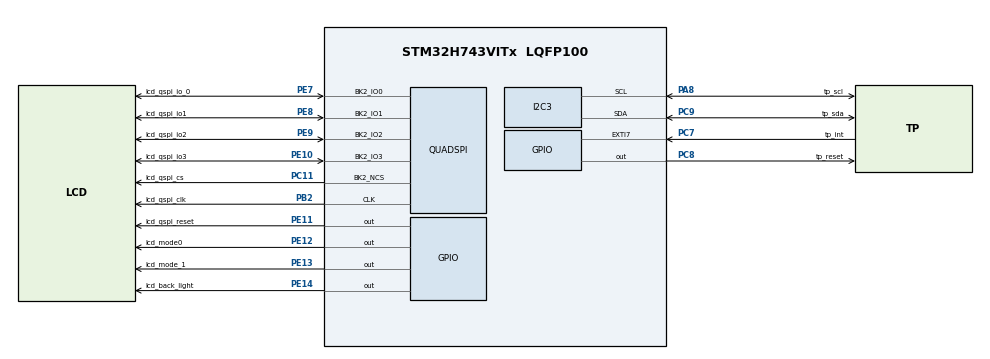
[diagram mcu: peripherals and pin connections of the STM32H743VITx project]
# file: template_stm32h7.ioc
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CORTEX_M7.default_mode_Activation=1
Dma.I2C3_RX.0.Direction=DMA_PERIPH_TO_MEMORY
Dma.I2C3_RX.0.EventEnable=DISABLE
Dma.I2C3_RX.0.FIFOMode=DMA_FIFOMODE_DISABLE
Dma.I2C3_RX.0.Instance=DMA1_Stream1
Dma.I2C3_RX.0.MemDataAlignment=DMA_MDATAALIGN_BYTE
Dma.I2C3_RX.0.MemInc=DMA_MINC_ENABLE
Dma.I2C3_RX.0.Mode=DMA_NORMAL
Dma.I2C3_RX.0.PeriphDataAlignment=DMA_PDATAALIGN_BYTE
Dma.I2C3_RX.0.PeriphInc=DMA_PINC_DISABLE
Dma.I2C3_RX.0.Polarity=HAL_DMAMUX_REQ_GEN_RISING
Dma.I2C3_RX.0.Priority=DMA_PRIORITY_MEDIUM
Dma.I2C3_RX.0.RequestNumber=1
Dma.I2C3_RX.0.SignalID=NONE
Dma.I2C3_RX.0.SyncEnable=DISABLE
Dma.I2C3_RX.0.SyncPolarity=HAL_DMAMUX_SYNC_NO_EVENT
Dma.I2C3_RX.0.SyncRequestNumber=1
Dma.I2C3_RX.0.SyncSignalID=NONE
Dma.Request0=I2C3_RX
FREERTOS.Queues01=queue_default,1,uint32_t,0,Dynamic,NULL,NULL
FREERTOS.Tasks01=task_default,24,128,task_default_start,Default,NULL,Dynamic,NULL,NULL
I2C3.CustomTiming=Disabled
I2C3.Speed=100
I2C3.Timing=0x307075B1
Mcu.Family=STM32H7
Mcu.Name=STM32H743VITx
Mcu.Package=LQFP100
NVIC.DMA1_Stream1_IRQn=true\:6\:0\:true\:false\:true\:true\:false\:true\:true
NVIC.EXTI9_5_IRQn=true\:7\:0\:true\:false\:true\:true\:true\:true\:true
NVIC.PriorityGroup=NVIC_PRIORITYGROUP_4
NVIC.TIM6_DAC_IRQn=true\:15\:0\:false\:false\:true\:false\:false\:true\:true
NVIC.TimeBase=TIM6_DAC_IRQn
NVIC.TimeBaseIP=TIM6
PA13\ (JTMS/SWDIO).Mode=Serial_Wire
PA13\ (JTMS/SWDIO).Signal=DEBUG_JTMS-SWDIO
PA14\ (JTCK/SWCLK).Mode=Serial_Wire
PA14\ (JTCK/SWCLK).Signal=DEBUG_JTCK-SWCLK
PA8.GPIO_Label=tp_scl
PA8.GPIO_Speed=GPIO_SPEED_FREQ_VERY_HIGH
PA8.Mode=I2C
PA8.Signal=I2C3_SCL
PB2.GPIO_Label=lcd_qspi_clk
PB2.GPIO_Speed=GPIO_SPEED_FREQ_VERY_HIGH
PB2.Mode=Single Bank 2
PB2.Signal=QUADSPI_CLK
PC11.GPIO_Label=lcd_qspi_cs
PC11.GPIO_PuPd=GPIO_PULLDOWN
PC11.GPIO_Speed=GPIO_SPEED_FREQ_VERY_HIGH
PC11.Mode=Single Bank 2
PC11.Signal=QUADSPI_BK2_NCS
PC14-OSC32_IN\ (OSC32_IN).Mode=LSE-External-Oscillator
PC14-OSC32_IN\ (OSC32_IN).Signal=RCC_OSC32_IN
PC15-OSC32_OUT\ (OSC32_OUT).Mode=LSE-External-Oscillator
PC15-OSC32_OUT\ (OSC32_OUT).Signal=RCC_OSC32_OUT
PC7.GPIO_Label=tp_int
PC7.GPIO_ModeDefaultEXTI=GPIO_MODE_IT_FALLING
PC7.GPIO_PuPd=GPIO_PULLUP
PC7.Signal=GPXTI7
PC8.GPIO_Label=tp_reset
PC8.GPIO_Speed=GPIO_SPEED_FREQ_VERY_HIGH
PC8.PinState=GPIO_PIN_SET
PC8.Signal=GPIO_Output
PC9.GPIO_Label=tp_sda
PC9.GPIO_Speed=GPIO_SPEED_FREQ_VERY_HIGH
PC9.Mode=I2C
PC9.Signal=I2C3_SDA
PE10.GPIO_Label=lcd_qspi_io3
PE10.GPIO_Speed=GPIO_SPEED_FREQ_VERY_HIGH
PE10.Mode=Single Bank 2
PE10.Signal=QUADSPI_BK2_IO3
PE11.GPIO_Label=lcd_qspi_reset
PE11.GPIO_Speed=GPIO_SPEED_FREQ_VERY_HIGH
PE11.PinState=GPIO_PIN_SET
PE11.Signal=GPIO_Output
PE12.GPIO_Label=lcd_mode0
PE12.GPIO_Speed=GPIO_SPEED_FREQ_VERY_HIGH
PE12.Signal=GPIO_Output
PE13.GPIO_Label=lcd_mode_1
PE13.GPIO_Speed=GPIO_SPEED_FREQ_VERY_HIGH
PE13.PinState=GPIO_PIN_SET
PE13.Signal=GPIO_Output
PE14.GPIO_Label=lcd_back_light
PE14.GPIO_Speed=GPIO_SPEED_FREQ_VERY_HIGH
PE14.PinState=GPIO_PIN_SET
PE14.Signal=GPIO_Output
PE7.GPIO_Label=lcd_qspi_io_0
PE7.GPIO_Speed=GPIO_SPEED_FREQ_VERY_HIGH
PE7.Mode=Single Bank 2
PE7.Signal=QUADSPI_BK2_IO0
PE8.GPIO_Label=lcd_qspi_io1
PE8.GPIO_Speed=GPIO_SPEED_FREQ_VERY_HIGH
PE8.Mode=Single Bank 2
PE8.Signal=QUADSPI_BK2_IO1
PE9.GPIO_Label=lcd_qspi_io2
PE9.GPIO_Speed=GPIO_SPEED_FREQ_VERY_HIGH
PE9.Mode=Single Bank 2
PE9.Signal=QUADSPI_BK2_IO2
PH0-OSC_IN\ (PH0).Mode=HSE-External-Oscillator
PH0-OSC_IN\ (PH0).Signal=RCC_OSC_IN
PH1-OSC_OUT\ (PH1).Mode=HSE-External-Oscillator
PH1-OSC_OUT\ (PH1).Signal=RCC_OSC_OUT
ProjectManager.HeapSize=0x200
ProjectManager.StackSize=0x400
ProjectManager.TargetToolchain=Makefile
RCC.ADCFreq_Value=100000000
RCC.APB1Freq_Value=120000000
RCC.APB2Freq_Value=120000000
RCC.APB3Freq_Value=120000000
RCC.APB4Freq_Value=120000000
RCC.CortexFreq_Value=480000000
RCC.D1PPRE=RCC_APB3_DIV2
RCC.D2PPRE1=RCC_APB1_DIV2
RCC.D2PPRE2=RCC_APB2_DIV2
RCC.D3PPRE=RCC_APB4_DIV2
RCC.DIVM1=5
RCC.DIVM2=16
RCC.DIVN1=192
RCC.DIVN2=128
RCC.DIVR2=4
RCC.HCLKFreq_Value=240000000
RCC.HPRE=RCC_HCLK_DIV2
RCC.PLLSourceVirtual=RCC_PLLSOURCE_HSE
RCC.QSPICLockSelection=RCC_QSPICLKSOURCE_PLL2
RCC.SYSCLKFreq_VALUE=480000000
RCC.SYSCLKSource=RCC_SYSCLKSOURCE_PLLCLK
RCC.USBFreq_Value=480000000
VP_FREERTOS_VS_CMSIS_V2.Mode=CMSIS_V2
VP_MEMORYMAP_VS_MEMORYMAP.Mode=CurAppReg
VP_RTC_VS_RTC_Activate.Mode=RTC_Enabled
VP_SYS_VS_tim6.Mode=TIM6
board=custom

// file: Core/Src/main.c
/* USER CODE BEGIN Header */
/**
  ******************************************************************************
  * @file           : main.c
  * @brief          : Main program body
  ******************************************************************************
  * @attention
  *
  * Copyright (c) 2025 STMicroelectronics.
  * All rights reserved.
  *
  * This software is licensed under terms that can be found in the LICENSE file
  * in the root directory of this software component.
  * If no LICENSE file comes with this software, it is provided AS-IS.
  *
  ******************************************************************************
  */
/* USER CODE END Header */
#include "main.h"
#include "cmsis_os.h"
#include "dma.h"
#include "i2c.h"
#include "memorymap.h"
#include "quadspi.h"
#include "rtc.h"
#include "gpio.h"

/* USER CODE BEGIN Includes */
#include "driver_st77916.h"
/* USER CODE END Includes */

void SystemClock_Config(void);
static void MPU_Config(void);
void MX_FREERTOS_Init(void);

int main(void)
{

  /* MPU Configuration--------------------------------------------------------*/
  MPU_Config();

  /* MCU Configuration--------------------------------------------------------*/

  /* Reset of all peripherals, Initializes the Flash interface and the Systick. */
  HAL_Init();

  /* Configure the system clock */
  SystemClock_Config();

  /* Initialize all configured peripherals */
  MX_GPIO_Init();
  MX_DMA_Init();
  MX_RTC_Init();
  MX_I2C3_Init();
  MX_QUADSPI_Init();
  /* USER CODE BEGIN 2 */
  driver_st77916_init();
  /* USER CODE END 2 */

  /* Init scheduler */
  osKernelInitialize();

  /* Call init function for freertos objects (in cmsis_os2.c) */
  MX_FREERTOS_Init();

  /* Start scheduler */
  osKernelStart();

  /* We should never get here as control is now taken by the scheduler */

  /* Infinite loop */
  while (1)
  {

  }
}

void SystemClock_Config(void)
{
  RCC_OscInitTypeDef RCC_OscInitStruct = {0};
  RCC_ClkInitTypeDef RCC_ClkInitStruct = {0};

  /** Supply configuration update enable
  */
  HAL_PWREx_ConfigSupply(PWR_LDO_SUPPLY);

  /** Configure the main internal regulator output voltage
  */
  __HAL_PWR_VOLTAGESCALING_CONFIG(PWR_REGULATOR_VOLTAGE_SCALE0);

  while(!__HAL_PWR_GET_FLAG(PWR_FLAG_VOSRDY)) {}

  /** Initializes the RCC Oscillators according to the specified parameters
  * in the RCC_OscInitTypeDef structure.
  */
  RCC_OscInitStruct.OscillatorType = RCC_OSCILLATORTYPE_LSI|RCC_OSCILLATORTYPE_HSE;
  RCC_OscInitStruct.HSEState = RCC_HSE_ON;
  RCC_OscInitStruct.LSIState = RCC_LSI_ON;
  RCC_OscInitStruct.PLL.PLLState = RCC_PLL_ON;
  RCC_OscInitStruct.PLL.PLLSource = RCC_PLLSOURCE_HSE;
  RCC_OscInitStruct.PLL.PLLM = 5;
  RCC_OscInitStruct.PLL.PLLN = 192;
  RCC_OscInitStruct.PLL.PLLP = 2;
  RCC_OscInitStruct.PLL.PLLQ = 2;
  RCC_OscInitStruct.PLL.PLLR = 2;
  RCC_OscInitStruct.PLL.PLLRGE = RCC_PLL1VCIRANGE_2;
  RCC_OscInitStruct.PLL.PLLVCOSEL = RCC_PLL1VCOWIDE;
  RCC_OscInitStruct.PLL.PLLFRACN = 0;
  if (HAL_RCC_OscConfig(&RCC_OscInitStruct) != HAL_OK)
  {
    Error_Handler();
  }

  /** Initializes the CPU, AHB and APB buses clocks
  */
  RCC_ClkInitStruct.ClockType = RCC_CLOCKTYPE_HCLK|RCC_CLOCKTYPE_SYSCLK
                              |RCC_CLOCKTYPE_PCLK1|RCC_CLOCKTYPE_PCLK2
                              |RCC_CLOCKTYPE_D3PCLK1|RCC_CLOCKTYPE_D1PCLK1;
  RCC_ClkInitStruct.SYSCLKSource = RCC_SYSCLKSOURCE_PLLCLK;
  RCC_ClkInitStruct.SYSCLKDivider = RCC_SYSCLK_DIV1;
  RCC_ClkInitStruct.AHBCLKDivider = RCC_HCLK_DIV2;
  RCC_ClkInitStruct.APB3CLKDivider = RCC_APB3_DIV2;
  RCC_ClkInitStruct.APB1CLKDivider = RCC_APB1_DIV2;
  RCC_ClkInitStruct.APB2CLKDivider = RCC_APB2_DIV2;
  RCC_ClkInitStruct.APB4CLKDivider = RCC_APB4_DIV2;

  if (HAL_RCC_ClockConfig(&RCC_ClkInitStruct, FLASH_LATENCY_4) != HAL_OK)
  {
    Error_Handler();
  }
}

 /* MPU Configuration */

void MPU_Config(void)
{
  MPU_Region_InitTypeDef MPU_InitStruct = {0};

  /* Disables the MPU */
  HAL_MPU_Disable();

  /** Initializes and configures the Region and the memory to be protected
  */
  MPU_InitStruct.Enable = MPU_REGION_ENABLE;
  MPU_InitStruct.Number = MPU_REGION_NUMBER0;
  MPU_InitStruct.BaseAddress = 0x0;
  MPU_InitStruct.Size = MPU_REGION_SIZE_4GB;
  MPU_InitStruct.SubRegionDisable = 0x87;
  MPU_InitStruct.TypeExtField = MPU_TEX_LEVEL0;
  MPU_InitStruct.AccessPermission = MPU_REGION_NO_ACCESS;
  MPU_InitStruct.DisableExec = MPU_INSTRUCTION_ACCESS_DISABLE;
  MPU_InitStruct.IsShareable = MPU_ACCESS_SHAREABLE;
  MPU_InitStruct.IsCacheable = MPU_ACCESS_NOT_CACHEABLE;
  MPU_InitStruct.IsBufferable = MPU_ACCESS_NOT_BUFFERABLE;

  HAL_MPU_ConfigRegion(&MPU_InitStruct);
  /* Enables the MPU */
  HAL_MPU_Enable(MPU_PRIVILEGED_DEFAULT);

}

void HAL_TIM_PeriodElapsedCallback(TIM_HandleTypeDef *htim)
{
  if (htim->Instance == TIM6)
  {
    HAL_IncTick();
  }
}

void Error_Handler(void)
{
  __disable_irq();
  while (1)
  {
  }
}

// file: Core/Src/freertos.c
/* USER CODE BEGIN Header */
/**
  ******************************************************************************
  * File Name          : freertos.c
  * Description        : Code for freertos applications
  ******************************************************************************
  * @attention
  *
  * Copyright (c) 2025 STMicroelectronics.
  * All rights reserved.
  *
  * This software is licensed under terms that can be found in the LICENSE file
  * in the root directory of this software component.
  * If no LICENSE file comes with this software, it is provided AS-IS.
  *
  ******************************************************************************
  */
/* USER CODE END Header */

#include "FreeRTOS.h"
#include "task.h"
#include "main.h"
#include "cmsis_os.h"

/* USER CODE BEGIN Includes */
#include "driver_st77916.h"
/* USER CODE END Includes */

/* Definitions for task_default */
osThreadId_t task_defaultHandle;
const osThreadAttr_t task_default_attributes = {
  .name = "task_default",
  .stack_size = 128 * 4,
  .priority = (osPriority_t) osPriorityNormal,
};
/* Definitions for queue_default */
osMessageQueueId_t queue_defaultHandle;
const osMessageQueueAttr_t queue_default_attributes = {
  .name = "queue_default"
};

void task_default_start(void *argument);

void MX_FREERTOS_Init(void); /* (MISRA C 2004 rule 8.1) */

void MX_FREERTOS_Init(void) {

  /* Create the queue(s) */
  /* creation of queue_default */
  queue_defaultHandle = osMessageQueueNew (1, sizeof(uint32_t), &queue_default_attributes);

  /* Create the thread(s) */
  /* creation of task_default */
  task_defaultHandle = osThreadNew(task_default_start, NULL, &task_default_attributes);

}

void task_default_start(void *argument)
{
  /* USER CODE BEGIN task_default_start */
  /* Infinite loop */
  for(;;)
  {
    driver_st77916_fillscreen(0xFF0000);
    //vTaskDelay(100);
  }
  /* USER CODE END task_default_start */
}
